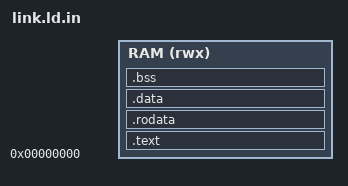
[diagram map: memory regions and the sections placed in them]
/* RV32u linker script (spec 08-software-flow.md). @RAM_BYTES@ is the RAM size of the
   chosen memory option (decision D1), filled in by sw/Makefile. Code and data share
   the one RAM; the stack grows down from the top. */
OUTPUT_ARCH("riscv")
ENTRY(_start)

MEMORY
{
  RAM (rwx) : ORIGIN = 0x00000000, LENGTH = @RAM_BYTES@
}

SECTIONS
{
  .text : {
    KEEP(*(.text.init))
    *(.text .text.*)
  } > RAM
  .rodata : ALIGN(4) { *(.rodata .rodata.* .srodata .srodata.*) } > RAM
  .data   : ALIGN(4) { *(.data .data.* .sdata .sdata.*) } > RAM
  .bss    : ALIGN(4) {
    __bss_start = .;
    *(.bss .bss.* .sbss .sbss.* COMMON)
    . = ALIGN(4);
    __bss_end = .;
  } > RAM
  __stack_top = ORIGIN(RAM) + LENGTH(RAM);
  /DISCARD/ : { *(.comment) *(.riscv.attributes) *(.note*) }
}
